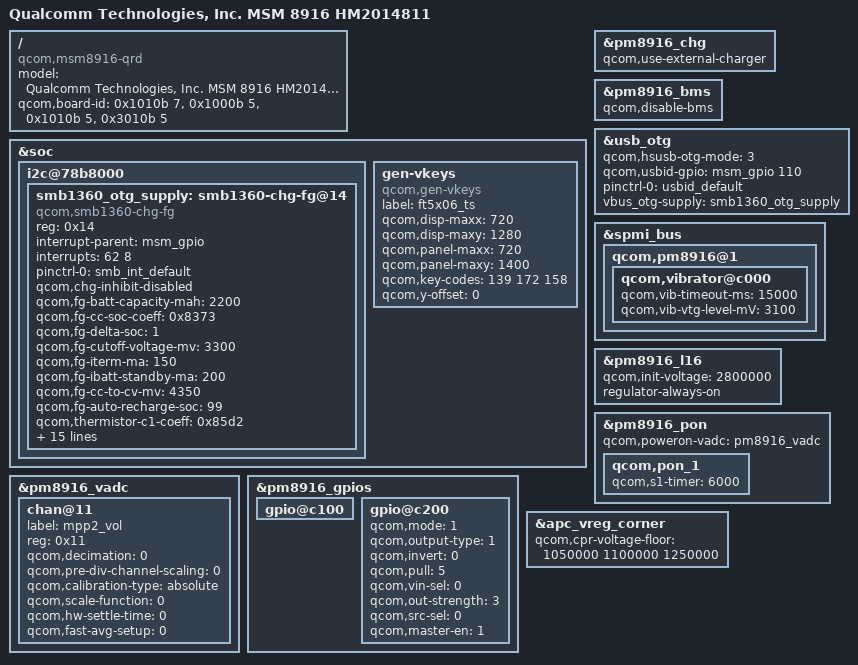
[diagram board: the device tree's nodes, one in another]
/* Copyright (c) 2014, The Linux Foundation. All rights reserved.
 *
 * This program is free software; you can redistribute it and/or modify
 * it under the terms of the GNU General Public License version 2 and
 * only version 2 as published by the Free Software Foundation.
 *
 * This program is distributed in the hope that it will be useful,
 * but WITHOUT ANY WARRANTY; without even the implied warranty of
 * MERCHANTABILITY or FITNESS FOR A PARTICULAR PURPOSE.  See the
 * GNU General Public License for more details.
 */

/dts-v1/;

#include "msm8916-qrd.dtsi"
#include "msm8916-memory.dtsi"
#include "hm2014811/msm8916-hm2014811.dtsi"

/ {
	model = "Qualcomm Technologies, Inc. MSM 8916 HM2014811";
	compatible = "qcom,msm8916-qrd", "qcom,msm8916", "qcom,qrd";
	qcom,board-id = <0x1010b 7>, <0x1000b 5>, <0x1010b 5>, <0x3010b 5>;
};

&soc {
	i2c@78b8000 {
		smb1360_otg_supply: smb1360-chg-fg@14 {
			compatible = "qcom,smb1360-chg-fg";
			reg = <0x14>;
			interrupt-parent = <&msm_gpio>;
			interrupts = <62 8>;
			pinctrl-names = "default";
			pinctrl-0 = <&smb_int_default>;
			qcom,chg-inhibit-disabled;
			qcom,fg-batt-capacity-mah = <2200>;
			qcom,fg-cc-soc-coeff = <0x8373>;
			qcom,fg-delta-soc = <1>;
			qcom,fg-cutoff-voltage-mv = <3300>;
			qcom,fg-iterm-ma = <150>;
			qcom,fg-ibatt-standby-ma = <200>;
			qcom,fg-cc-to-cv-mv = <4350>;
			qcom,fg-auto-recharge-soc = <99>;
			qcom,thermistor-c1-coeff = <0x85d2>;
			qcom,float-voltage-mv = <4350>;
			qcom,iterm-ma = <100>;
			qcom,thermal-mitigation = <1500 700 600 0>;
			qcom,config-hard-thresholds;
			qcom,hot-bat-decidegc = <590>;
			qcom,cold-bat-decidegc = <0>;
			qcom,soft-jeita-supported;
			qcom,warm-bat-decidegc = <510>;
			qcom,cool-bat-decidegc = <100>;
			qcom,warm-bat-mv = <4350>;
			qcom,cool-bat-mv = <4350>;
			qcom,warm-bat-ma = <600>;
			qcom,cool-bat-ma = <600>;
			regulator-name = "smb1360_otg_vreg";
			qcom,shdn-after-pwroff;
		};
	};

	gen-vkeys {
		compatible = "qcom,gen-vkeys";
		label = "ft5x06_ts";
		qcom,disp-maxx = <720>;
		qcom,disp-maxy = <1280>;
		qcom,panel-maxx = <720>;
		qcom,panel-maxy = <1400>;
		qcom,key-codes = <139 172 158>;
		qcom,y-offset = <0>;
	};
};

&pm8916_chg {
	status = "ok";
	qcom,use-external-charger;
};

&pm8916_bms {
	status = "ok";
	qcom,disable-bms;
};

&usb_otg {
	qcom,hsusb-otg-mode = <3>;
	qcom,usbid-gpio = <&msm_gpio 110 0>;
	pinctrl-names = "default";
	pinctrl-0 = <&usbid_default>;
	vbus_otg-supply = <&smb1360_otg_supply>;
};

&spmi_bus {
	qcom,pm8916@1 {
		qcom,vibrator@c000 {
			status = "okay";
			qcom,vib-timeout-ms = <15000>;
			qcom,vib-vtg-level-mV = <3100>;
		};
	};
};

&pm8916_l16 {
	qcom,init-voltage = <2800000>;
	regulator-always-on;
};

&pm8916_pon {
	/delete-property/ qcom,store-hard-reset-reason;
	qcom,poweron-vadc = <&pm8916_vadc>;

	qcom,pon_1 {
		qcom,s1-timer = <6000>;
	};
};

&pm8916_vadc {
	chan@11 {
		label = "mpp2_vol";
		reg = <0x11>;
		qcom,decimation = <0>;
		qcom,pre-div-channel-scaling = <0>;
		qcom,calibration-type = "absolute";
		qcom,scale-function = <0>;
		qcom,hw-settle-time = <0>;
		qcom,fast-avg-setup = <0>;
	};
};

&pm8916_gpios {
	gpio@c100 { /* GPIO 2 */
		/* NFC_CLK_REQ */
		status = "ok";
	};

	gpio@c200 { /* GPIO 3 */
		/* External regulator control for WTR */
		qcom,mode = <1>;
		qcom,output-type = <1>;
		qcom,invert = <0>;
		qcom,pull = <5>;
		qcom,vin-sel = <0>;
		qcom,out-strength = <3>;
		qcom,src-sel = <0>;
		qcom,master-en = <1>;
		status = "ok";
	};
};

&apc_vreg_corner {
	qcom,cpr-voltage-floor = <1050000 1100000 1250000>;
};
